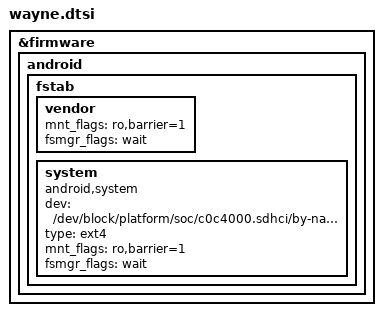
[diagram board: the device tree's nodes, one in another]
/* Copyright (c) 2019, The Linux Foundation. All rights reserved.
 *
 * This program is free software; you can redistribute it and/or modify
 * it under the terms of the GNU General Public License version 2 and
 * only version 2 as published by the Free Software Foundation.
 *
 * This program is distributed in the hope that it will be useful,
 * but WITHOUT ANY WARRANTY; without even the implied warranty of
 * MERCHANTABILITY or FITNESS FOR A PARTICULAR PURPOSE.  See the
 * GNU General Public License for more details.
 */

#include "xiaomi-sdm660-common.dtsi"
#include "longcheer/common/longcheer-sdm660-base.dtsi"
#include "longcheer/wayne/wayne-common-base.dtsi"

/* sdm660.dtsi wayne specific diff */
&firmware {
	android {
		/delete-node/ vbmeta;
		fstab {
			vendor {
				mnt_flags = "ro,barrier=1";
				fsmgr_flags = "wait";
			};

			system {
				compatible = "android,system";
				dev = "/dev/block/platform/soc/c0c4000.sdhci/by-name/system";
				type = "ext4";
				mnt_flags = "ro,barrier=1";
				fsmgr_flags = "wait";
				status = "ok";
			};
		};
	};
};
